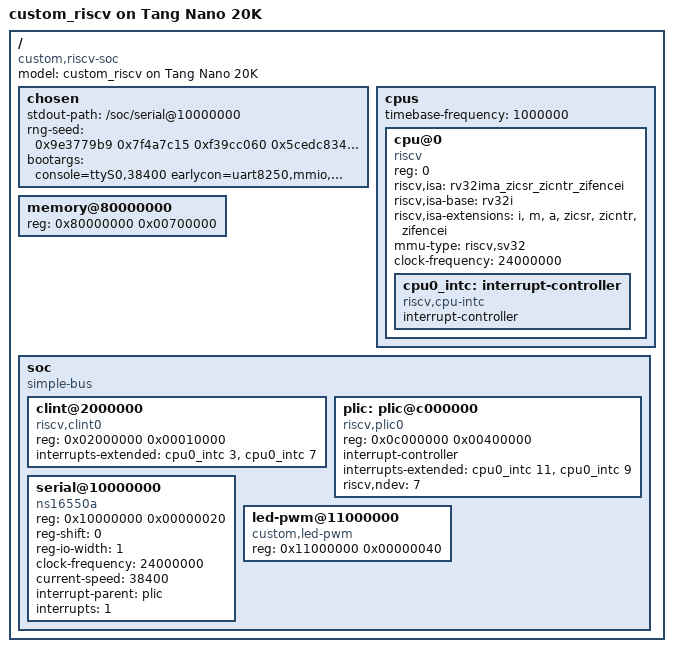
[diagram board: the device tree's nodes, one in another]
/dts-v1/;

/*
 * Device tree for booting Linux on the custom_riscv SoC.
 *
 * Separate from custom_riscv.dts, which describes the machine for a bare-metal
 * BIOS and for OpenSBI on its own. The difference that matters is the memory
 * node, and it is not cosmetic.
 *
 * --- Why memory is 7 MiB and not 8 -----------------------------------------
 *
 * There are 8 MiB of SDRAM. Linux is told about 7, because OpenSBI lives in the
 * eighth and Linux must never allocate there.
 *
 * The layout is forced. RV32's setup_vm maps kernel text with Sv32 megapages, so
 * the load address has to be 4 MiB aligned - it is a BUG_ON, not a warning - and
 * with 8 MiB starting at 0x8000_0000 there are exactly two legal slots. A 4 MB
 * Image only fits in the first. So the kernel takes the base of memory and
 * OpenSBI is pushed to the top, which is the reverse of the usual arrangement.
 *
 * Declaring all 8 MiB and relying on OpenSBI's reserved-memory fixup was tried
 * and did not hold: Linux allocated over the firmware and zeroed it. The failure
 * was memorable - the next SBI call trapped to mtvec, found a page of zeroes,
 * raised an illegal instruction, vectored to mtvec again, and looped there
 * forever with no instruction retiring and nothing printed. Excluding the region
 * outright means there is nothing to get wrong.
 *
 *     0x8000_0000  kernel Image           (4 MiB aligned, ~4.0 MB)
 *     0x8040_0000  initrd, if one is used
 *     0x806F_0000  device tree            (inside memory, so Linux reserves it)
 *     0x8070_0000  OpenSBI                (outside memory - invisible to Linux)
 *     0x8080_0000  end of SDRAM
 */

/ {
	#address-cells = <1>;
	#size-cells = <1>;
	compatible = "custom,riscv-soc";
	model = "custom_riscv on Tang Nano 20K";

	chosen {
		stdout-path = "/soc/serial@10000000";
		/*
		 * earlycon is worth more than everything else on this line: it is
		 * the only output between the kernel's first instruction and the
		 * 8250 driver probing, which is where a new machine fails.
		 *
		 * No root= : the rootfs is an initramfs, so the kernel unpacks it
		 * into a tmpfs and runs /init from there. There is no block driver
		 * for the SD controller, and 8 MiB of RAM has no room for a page
		 * cache over one anyway.
		 */
		/*
		 * The baud belongs on console=, and must NOT be on earlycon.
		 *
		 * console=hvc0, not ttyS0, and that is the whole point.
		 *
		 * Kernel printk reaches the wire through uart_console_write(),
		 * which polls the THRE bit directly. Userspace output does not: a
		 * write() lands in the tty's circular buffer, and the only thing
		 * that moves it to the UART is serial8250_start_tx() enabling the
		 * THRI interrupt and the handler draining it. With no working UART
		 * interrupt the buffer simply fills and nothing is ever sent -
		 * which is a flawless 60-second boot log followed by absolute
		 * silence the moment /sbin/init starts.
		 *
		 * Setting irq=0 does not help. univ8250_setup_irq() returns early
		 * and univ8250_setup_timer() only arms the backup timer when
		 * up->bugs & UART_BUG_THRE is set, so a polled port has neither an
		 * interrupt nor a timer draining it.
		 *
		 * hvc0 (CONFIG_HVC_RISCV_SBI) routes every character through
		 * OpenSBI's DBCN extension, which writes the UART from M-mode by
		 * polling. It touches none of our interrupt path, which is why it
		 * is the console here until that path is proven.
		 *
		 * rdinit=/bin/sh, not /sbin/init, and this is a deliberate
		 * narrowing rather than the final configuration.
		 *
		 * The evidence says init is alive: the kernel prints "Run
		 * /sbin/init as init process" *before* calling kernel_execve(),
		 * and a failure there would print "Failed to execute" and then
		 * panic with "No working init found". An init that exited would
		 * panic with "Attempted to kill init". None of those appear, so
		 * execve succeeded and the process is still running - it simply
		 * never produces output, not even the /dev/kmsg write in rcS,
		 * which goes through printk rather than the tty.
		 *
		 * That places the stall at init's first fork()+execve() of the
		 * shell for the sysinit action. /bin/sh as init removes the fork,
		 * the inittab parse and the rcS shell from the path: one execve
		 * of the same binary, then a prompt. If that prompt appears, the
		 * binary and the console are both fine and the fault is in the
		 * fork path; if it does not, the fault is in exec-to-userspace
		 * and the busybox layer was never the issue.
		 *
		 * NO keep_bootcon. Two consoles on one UART is two unsynchronized
		 * writers on one THR, and they interleave into garbage.
		 *
		 * earlycon writes from printk context. hvc0 does not: userspace
		 * output is drained by the khvcd kernel thread, which calls
		 * sbi_debug_console_write() from its own context with no lock
		 * shared with printk. With keep_bootcon set, the duplicate kernel
		 * lines are the harmless symptom and the corrupted userspace
		 * output is the real one. Without it, earlycon is handed over and
		 * disabled the moment hvc0 registers, leaving exactly one writer.
		 *
		 * On the clocks, for when ttyS0 comes back:
		 *
		 * console=ttyS0 is the real 8250 driver on an of_serial device, so
		 * it reads clock-frequency from this node and computes
		 * 1500000/38400 = 39, i.e. 38461 baud - 0.16% off, fine. Leaving
		 * the baud off *this* one is what made the driver reprogram the
		 * port to its own default, and everything after "is a 16550A" was
		 * garbage.
		 *
		 * earlycon has no node to read, so when it is given a baud
		 * parse_options() assumes uartclk = BASE_BAUD*16 = 1843200 and
		 * gets divisor 1843200/(16*38400) = 3. On our real 24 MHz clock
		 * that divisor is 500000 baud - 13x too fast - and the very first
		 * kernel character is garbage, immediately after OpenSBI's last
		 * clean line. Given no baud, early_serial8250_setup() skips
		 * init_port() and inherits the divisor the BIOS already set, which
		 * is correct by construction because the BIOS set the rate the
		 * console is being watched at.
		 */
		/*
		 * Seed for the kernel's RNG. This machine has no entropy source
		 * the kernel recognises, so without it the CRNG stays unseeded
		 * through the whole boot - and while it is unseeded, every
		 * get_random_u32() bypasses the per-cpu batch and runs a full
		 * BLAKE2s extraction of the input pool. Every new inode asks for
		 * one, so each devtmpfs node paid for a hash; under PC sampling
		 * blake2s_compress_generic was the single hottest function of the
		 * boot. drivers/of/fdt.c hands this to add_bootloader_randomness(),
		 * which credits it (random.trust_bootloader defaults on) and the
		 * kernel then erases it from the tree.
		 *
		 * It is a constant, so it is not a secret and every boot draws the
		 * same random numbers. Right for a development board; anything
		 * that needs real randomness wants the BIOS to fill this in.
		 */
		rng-seed = <0x9e3779b9 0x7f4a7c15 0xf39cc060 0x5cedc834
			    0x1082276b 0xf3a27251 0xf86c6a11 0xd0c18e95>;
		bootargs = "console=ttyS0,38400 earlycon=uart8250,mmio,0x10000000 loglevel=8 rdinit=/init";
	};

	cpus {
		#address-cells = <1>;
		#size-cells = <0>;
		timebase-frequency = <1000000>;		/* CLINT mtime, 1 MHz */

		cpu@0 {
			device_type = "cpu";
			compatible = "riscv";
			reg = <0>;
			riscv,isa = "rv32ima_zicsr_zicntr_zifencei";
			riscv,isa-base = "rv32i";
			riscv,isa-extensions = "i", "m", "a", "zicsr", "zicntr", "zifencei";
			/*
			 * Deliberately no "c". This core has no compressed
			 * instructions, and a kernel or libc built with them
			 * faults on the first one - which looks like a crash at
			 * a random address rather than a missing extension.
			 */
			mmu-type = "riscv,sv32";
			clock-frequency = <24000000>;
			status = "okay";

			cpu0_intc: interrupt-controller {
				compatible = "riscv,cpu-intc";
				interrupt-controller;
				#interrupt-cells = <1>;
			};
		};
	};

	/* 7 of the 8 MiB. The eighth holds OpenSBI - see the note above. */
	memory@80000000 {
		device_type = "memory";
		reg = <0x80000000 0x00700000>;
	};

	soc {
		compatible = "simple-bus";
		#address-cells = <1>;
		#size-cells = <1>;
		ranges;

		clint@2000000 {
			compatible = "riscv,clint0";
			reg = <0x02000000 0x00010000>;
			interrupts-extended = <&cpu0_intc 3 &cpu0_intc 7>;
		};

		plic: plic@c000000 {
			compatible = "riscv,plic0";
			reg = <0x0c000000 0x00400000>;
			interrupt-controller;
			#interrupt-cells = <1>;
			#address-cells = <0>;
			/*
			 * Context 0 is hart 0 machine mode, context 1 is hart 0
			 * supervisor mode, in that order. Linux drives the
			 * supervisor one; with only the machine entry present it
			 * finds no context of its own and every device interrupt
			 * goes nowhere.
			 */
			interrupts-extended = <&cpu0_intc 11 &cpu0_intc 9>;
			riscv,ndev = <7>;
		};

		/*
		 * OpenCores 16550, byte addressed: register N is at base + N, so
		 * reg-shift is 0 and reg-io-width is 1. clock-frequency is the
		 * UART's input clock, not the baud rate - the driver divides it.
		 *
		 * current-speed must be here, and must be right. OpenSBI's
		 * uart8250 driver takes the baud from it, and with the property
		 * absent it brings up no console at all - it then boots perfectly
		 * and silently, which is a genuinely confusing thing to debug: the
		 * instruction count climbs and not one character appears.
		 *
		 * The value is patched for simulation by the Makefile, for the same
		 * reason $(DTB_SIM) does it: simulation transmits at the real bit
		 * rate, so 38400 baud would make a few hundred characters dominate
		 * the whole run.
		 */
		serial@10000000 {
			compatible = "ns16550a";
			reg = <0x10000000 0x00000020>;
			reg-shift = <0>;
			reg-io-width = <1>;
			clock-frequency = <24000000>;
			current-speed = <38400>;
			interrupt-parent = <&plic>;
			interrupts = <1>;
			status = "okay";
		};

		led-pwm@11000000 {
			compatible = "custom,led-pwm";
			reg = <0x11000000 0x00000040>;
			status = "okay";
		};
	};
};
